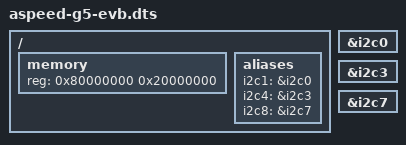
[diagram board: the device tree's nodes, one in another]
/dts-v1/;

#include "aspeed-g5.dtsi"

/ {
	memory {
		device_type = "memory";
		reg = <0x80000000 0x20000000>;
	};

	aliases {
		i2c1 = &i2c0;
		i2c4 = &i2c3;
		i2c8 = &i2c7;
	};
};

&i2c0 {
	status = "okay";
};

&i2c3 {
	status = "okay";
};

&i2c7 {
	status = "okay";
};
